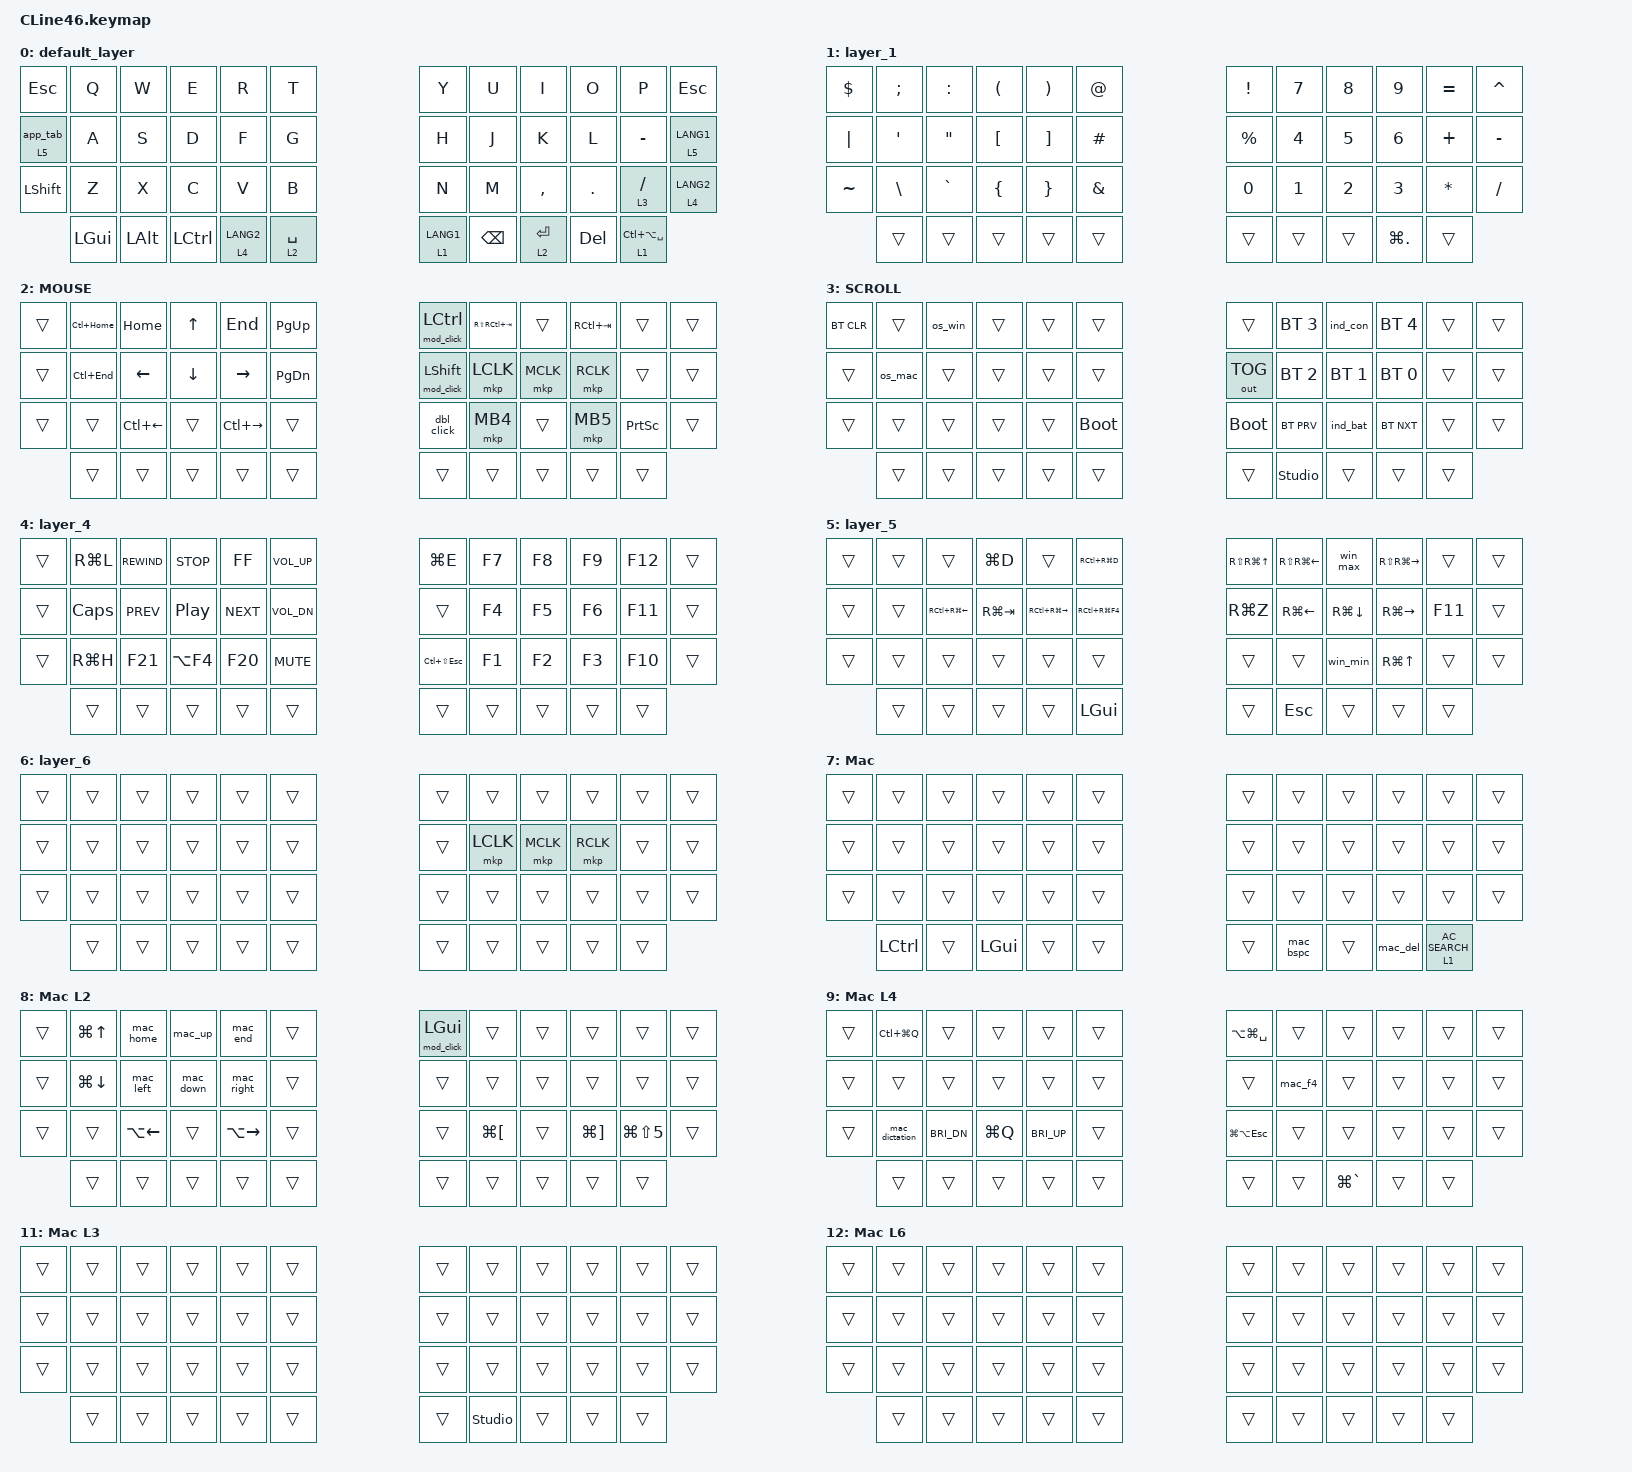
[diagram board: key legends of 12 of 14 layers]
#include <input/processors.dtsi>
#include <dt-bindings/zmk/input_transform.h>
#include <zephyr/dt-bindings/input/input-event-codes.h>
#include <behaviors.dtsi>
#include <dt-bindings/zmk/bt.h>
#include <dt-bindings/zmk/outputs.h>
#include <behaviors/rgbled_widget.dtsi>
#include <dt-bindings/zmk/keys.h>
#include <dt-bindings/zmk/pointing.h>

// ---------------------------------------------------------------------------
// レイヤー構成
//   0〜6 : 共通(Windows基準)。DYAStudio で編集してきた配列を書き写したもの
//   7    : Macモード(Windows/Macモード切替キーでON/OFF。状態は電源を切っても保持)
//   8〜12: Macモード中に、対応するレイヤーの上に自動で重なる差し替え用レイヤー
//          8 = L2(矢印・マウス)、9 = L4(メディア・F)、10 = L5(ウィンドウ操作)、11 = L3(BT)、
//          12 = L6(マウス)
// 7〜12 も DYAStudio で中身を編集できる。▽(透過)にしたキーは下のレイヤーのキーになる
// ---------------------------------------------------------------------------
#define MAC 7

// 長押しキー(A・Z など)の誤爆対策: 直前のキーから 150ms 以内に押したら長押し判定をせず、すぐ文字にする
// quick-tap: 1回タップして 200ms 以内にもう一度押したまま → 長押しではなくそのキーの押しっぱなし(連打)
&lt {
    require-prior-idle-ms = <150>;
    quick-tap-ms = <200>;
};

&mt {
    flavor = "balanced";
    quick-tap-ms = <0>;
};

/ {
    combos {
        compatible = "zmk,combos";

        tab {
            bindings = <&kp TAB>;
            key-positions = <11 12>;
        };

        shift_tab {
            bindings = <&kp LS(TAB)>;
            key-positions = <12 13>;
        };
    };

    conditional_layers {
        compatible = "zmk,conditional-layers";

        mac_nav {
            if-layers = <2 MAC>;
            then-layer = <8>;
        };

        mac_fn {
            if-layers = <4 MAC>;
            then-layer = <9>;
        };

        mac_win {
            if-layers = <5 MAC>;
            then-layer = <10>;
        };

        mac_bt {
            if-layers = <3 MAC>;
            then-layer = <11>;
        };

        mac_mouse {
            if-layers = <6 MAC>;
            then-layer = <12>;
        };

        mac_sym {
            if-layers = <1 MAC>;
            then-layer = <13>;
        };
    };

    macros {
        to_layer_0: to_layer_0 {
            compatible = "zmk,behavior-macro-one-param";
            #binding-cells = <1>;
            bindings = <&to 0 &macro_param_1to1 &kp MACRO_PLACEHOLDER>;
            label = "TO_LAYER_0";
        };

        // Mac: 音声入力(システム設定で「Controlキーを2回押す」にしておく)
        mac_dictation: mac_dictation {
            compatible = "zmk,behavior-macro";
            #binding-cells = <0>;
            display-name = "Mac Dictation";
            // 速すぎると macOS が2回押しと認識しないので、間隔を空ける
            wait-ms = <120>;
            tap-ms = <50>;
            bindings = <&macro_tap &kp LCTRL &kp LCTRL>;
        };

        // 修飾キーを押したまま左クリック(Layer 2 右手)。押している間はボタンも押しっぱなしなのでドラッグもできる
        mod_click: mod_click {
            compatible = "zmk,behavior-macro-one-param";
            #binding-cells = <1>;
            display-name = "Mod Click";
            wait-ms = <20>;
            tap-ms = <20>;
            bindings
                = <&macro_param_1to1 &macro_press &kp MACRO_PLACEHOLDER>
                , <&macro_press &mkp LCLK>
                , <&macro_pause_for_release>
                , <&macro_release &mkp LCLK>
                , <&macro_param_1to1 &macro_release &kp MACRO_PLACEHOLDER>
                ;
        };

        // Windows: 一発で画面全体に最大化(ウィンドウメニュー Alt+Space → 最大化(X))。
        // Win+↑ と違い、スナップ中でも最大化ボタンと同じ動きになる。
        // そのウィンドウで初めて開くメニューは表示が遅い(新しいウィンドウを別デスクトップへ移した直後など)ので、
        // 1.5 秒待ってから X を 0.1 秒押す(0.8 秒 / 0.03 秒では取りこぼしてメニューが開いたままになった)
        win_max: win_max {
            compatible = "zmk,behavior-macro";
            #binding-cells = <0>;
            display-name = "Maximize";
            wait-ms = <30>;
            tap-ms = <100>;
            bindings = <&macro_tap &kp LA(SPACE)>, <&macro_wait_time 1500>, <&macro_tap &kp X>;
        };

        // Windows: 最小化(ウィンドウメニュー Alt+Space → 最小化(N))。Win+↓ と違い、最大化中でも一発で最小化する。待ち時間は win_max と同じ
        win_min: win_min {
            compatible = "zmk,behavior-macro";
            #binding-cells = <0>;
            display-name = "Minimize";
            wait-ms = <30>;
            tap-ms = <100>;
            bindings = <&macro_tap &kp LA(SPACE)>, <&macro_wait_time 1500>, <&macro_tap &kp N>;
        };

        // 左ダブルクリック(Layer 2 右手)
        dbl_click: dbl_click {
            compatible = "zmk,behavior-macro";
            #binding-cells = <0>;
            display-name = "Double Click";
            wait-ms = <30>;
            tap-ms = <30>;
            bindings = <&macro_tap &mkp LCLK &mkp LCLK>;
        };

    };

    behaviors {
        lt_to_layer_0: lt_to_layer_0 {
            compatible = "zmk,behavior-hold-tap";
            label = "LAYER_TAP_TO_0";
            bindings = <&mo>, <&to_layer_0>;

            #binding-cells = <2>;
            tapping-term-ms = <200>;
            require-prior-idle-ms = <150>;
        };

        // 左 Tab: タップは App Tab、長押しはレイヤー(L5)。&lt と同じ誤爆対策を入れる
        //   使い方: &lt_app_tab 5 0(2つ目の値は使わない)
        lt_app_tab: lt_app_tab {
            compatible = "zmk,behavior-hold-tap";
            display-name = "Layer Tap App Tab";
            bindings = <&mo>, <&app_tab>;

            #binding-cells = <2>;
            flavor = "tap-preferred";
            tapping-term-ms = <200>;
            require-prior-idle-ms = <150>;
            quick-tap-ms = <200>;
        };

        // Windows/Mac モード切替
        os_win: os_win {
            compatible = "cline46,behavior-os-mode";
            #binding-cells = <0>;
            display-name = "Windows Mode";
            layer = <MAC>;
        };

        os_mac: os_mac {
            compatible = "cline46,behavior-os-mode";
            #binding-cells = <0>;
            display-name = "Mac Mode";
            layer = <MAC>;
            mac-mode;
        };

        // アプリ切替用 Tab。Mac の Cmd+Tab と同じ指(Ctrl の位置+Tab)で切り替える
        //   Windows: Ctrl+Tab → Alt+Tab / Mac: Alt+Tab → Cmd+Tab(修飾キーを離すまで切替画面を開いたまま)
        app_tab: app_tab {
            compatible = "cline46,behavior-app-tab";
            #binding-cells = <0>;
            display-name = "App Tab";
        };

        // Mac モードでは Ctrl の位置のキーが Cmd を送る。
        // Windows の Ctrl+矢印 / Ctrl+Backspace などを Mac の同じ動作に変換する
        mac_left: mac_left {
            compatible = "zmk,behavior-mod-morph";
            #binding-cells = <0>;
            display-name = "Mac Left";
            bindings = <&kp LEFT>, <&kp LA(LEFT)>;
            mods = <(MOD_LGUI|MOD_RGUI)>;
        };

        mac_right: mac_right {
            compatible = "zmk,behavior-mod-morph";
            #binding-cells = <0>;
            display-name = "Mac Right";
            bindings = <&kp RIGHT>, <&kp LA(RIGHT)>;
            mods = <(MOD_LGUI|MOD_RGUI)>;
        };

        mac_up: mac_up {
            compatible = "zmk,behavior-mod-morph";
            #binding-cells = <0>;
            display-name = "Mac Up";
            bindings = <&kp UP>, <&kp LA(UP)>;
            mods = <(MOD_LGUI|MOD_RGUI)>;
        };

        mac_down: mac_down {
            compatible = "zmk,behavior-mod-morph";
            #binding-cells = <0>;
            display-name = "Mac Down";
            bindings = <&kp DOWN>, <&kp LA(DOWN)>;
            mods = <(MOD_LGUI|MOD_RGUI)>;
        };

        // Home = 行頭(Cmd+←)、Ctrl+Home = 文書の先頭(Cmd+↑)
        mac_home: mac_home {
            compatible = "zmk,behavior-mod-morph";
            #binding-cells = <0>;
            display-name = "Mac Home";
            bindings = <&kp LG(LEFT)>, <&kp LG(UP)>;
            mods = <(MOD_LGUI|MOD_RGUI)>;
        };

        // End = 行末(Cmd+→)、Ctrl+End = 文書の末尾(Cmd+↓)
        mac_end: mac_end {
            compatible = "zmk,behavior-mod-morph";
            #binding-cells = <0>;
            display-name = "Mac End";
            bindings = <&kp LG(RIGHT)>, <&kp LG(DOWN)>;
            mods = <(MOD_LGUI|MOD_RGUI)>;
        };

        mac_bspc: mac_bspc {
            compatible = "zmk,behavior-mod-morph";
            #binding-cells = <0>;
            display-name = "Mac Backspace";
            bindings = <&kp BSPC>, <&kp LA(BSPC)>;
            mods = <(MOD_LGUI|MOD_RGUI)>;
        };

        mac_del: mac_del {
            compatible = "zmk,behavior-mod-morph";
            #binding-cells = <0>;
            display-name = "Mac Delete";
            bindings = <&kp DEL>, <&kp LA(DEL)>;
            mods = <(MOD_LGUI|MOD_RGUI)>;
        };

        // Alt+F4 → Cmd+Q
        mac_f4: mac_f4 {
            compatible = "zmk,behavior-mod-morph";
            #binding-cells = <0>;
            display-name = "Mac F4";
            bindings = <&kp F4>, <&kp LG(Q)>;
            mods = <(MOD_LALT|MOD_RALT)>;
        };
    };

    keymap {
        compatible = "zmk,keymap";

        // 長押しは左右でほぼ同じ位置に置く
        //   Space / Enter = L2、左Tab / 右Tab位置 = L5、"/" = L3、英数 / 右Shift位置 = L4、かな / 🔍 = L1
        //   左Tab のタップは App Tab。A と Z は誤爆するので長押しなし(Z は Google 日本語入力の z+h / l とぶつかる)
        //   右Tab位置のタップはかな、右Shift位置のタップは英数(左親指の英数・かなと同じキー)
        //   🔍 のタップは Windows では PowerToys Run(Ctrl+Alt+Space)、Mac では Spotlight
        default_layer {
            bindings = <
&kp ESC          &kp Q   &kp W  &kp E      &kp R        &kp T                                           &kp Y      &kp U       &kp I      &kp O    &kp P          &kp ESC
&lt_app_tab 5 0  &kp A   &kp S  &kp D      &kp F        &kp G                                           &kp H      &kp J       &kp K      &kp L    &kp MINUS      &lt 5 LANG1
&kp LSHIFT       &kp Z   &kp X  &kp C      &kp V        &kp B                                           &kp N      &kp M       &kp COMMA  &kp DOT  &lt 3 SLASH    &lt 4 LANG2
             &kp LGUI      &kp LALT   &kp LCTRL    &lt 4 LANG2  &lt 2 SPACE  &lt 1 LANG1    &kp BSPC   &lt 2 RET                         &kp DEL  &lt 1 LC(LA(SPACE))
            >;
        };

        layer_1 {
            bindings = <
&kp DLLR   &kp SEMI  &kp COLON  &kp LPAR  &kp RPAR  &kp AT                         &kp EXCL   &kp N7  &kp N8  &kp N9  &kp EQUAL  &kp CARET
&kp PIPE   &kp SQT   &kp DQT    &kp LBKT  &kp RBKT  &kp HASH                       &kp PRCNT  &kp N4  &kp N5  &kp N6  &kp PLUS   &kp MINUS
&kp TILDE  &kp BSLH  &kp GRAVE  &kp LBRC  &kp RBRC  &kp AMPS                       &kp N0     &kp N1  &kp N2  &kp N3  &kp STAR   &kp SLASH
        &trans    &trans     &trans    &trans    &trans    &trans     &trans    &trans                     &kp LG(DOT)  &trans
            >;
        };

        // 2: 矢印・マウス。左手: Q/A=文書の先頭/末尾、W/R=Home/End、T/G=PgUp/PgDn、X/V=単語左/右
        //    右手の / = スクショ(PrtSc)
        MOUSE {
            bindings = <
&trans  &kp LC(HOME)  &kp HOME   &kp UP    &kp END    &kp PG_UP                &mod_click LCTRL &kp RS(RC(TAB))  &trans    &kp RC(TAB)  &trans      &trans
&trans  &kp LC(END)   &kp LEFT   &kp DOWN  &kp RIGHT  &kp PG_DN                &mod_click LSHIFT &mkp LCLK        &mkp MCLK &mkp RCLK    &trans      &trans
&trans  &trans        &kp LC(LEFT) &trans  &kp LC(RIGHT) &trans                &dbl_click       &mkp MB4         &trans    &mkp MB5     &kp PSCRN   &trans
        &trans  &trans     &trans    &trans     &trans   &trans      &trans     &trans                                 &trans       &trans
            >;
        };

        SCROLL {
            bindings = <
&bt BT_CLR      &trans  &os_win  &trans  &trans  &trans                        &trans  &bt BT_SEL 3  &ind_con      &bt BT_SEL 4  &trans  &trans
&trans          &os_mac &trans   &trans  &trans  &trans                        &out OUT_TOG  &bt BT_SEL 2  &bt BT_SEL 1  &bt BT_SEL 0  &trans  &trans
&trans          &trans  &trans   &trans  &trans  &bootloader                   &bootloader  &bt BT_PRV    &ind_bat      &bt BT_NXT    &trans  &trans
                &trans  &trans   &trans  &trans  &trans  &trans      &studio_unlock  &trans                        &trans        &trans
            >;
        };

        // 4: メディア・ファンクション。右手内側の列は Y=エクスプローラー N=タスクマネージャー
        layer_4 {
            bindings = <
&trans  &kp RG(L)  &kp C_REWIND  &kp C_STOP  &kp C_FF    &kp C_VOL_UP                     &kp LG(E)        &kp F7  &kp F8  &kp F9  &kp F12  &trans
&trans  &kp CAPS   &kp C_PREV    &kp C_PP    &kp C_NEXT  &kp C_VOL_DN                     &trans           &kp F4  &kp F5  &kp F6  &kp F11  &trans
&trans  &kp RG(H)  &kp F21       &kp LA(F4)  &kp F20     &kp C_MUTE                       &kp LC(LS(ESC))  &kp F1  &kp F2  &kp F3  &kp F10  &trans
        &trans     &trans        &trans      &trans      &trans    &trans      &trans     &trans                  &trans  &trans
            >;
        };

        // 5: ウィンドウ操作(左Tab / 右Tab位置の長押し)
        //    小指で長押ししたまま押すので、よく使うキーは人差し指・中指の列に置く
        //    右手 = ウィンドウの移動・サイズ。矢印の形で I=最大化 J/L=左右スナップ K=元に戻す(Win+↓) ,=最小化、
        //      U/O=別モニタへ、Y=縦に最大化、H=スナップレイアウト、-=全画面(F11)、
        //      .=Win+↑(スナップ中は 1/4 に縮める)
        //    左手 = 仮想デスクトップ。右手の J/K/L と同じく S/F=前/次、D=タスクビュー、E=デスクトップ表示、T/G=作成/削除
        //    親指 = Space の位置がスタート、Backspace の位置が Esc(スナップ後の候補を閉じる)。Enter はそのまま Enter(候補を選ぶ)
        layer_5 {
            bindings = <
&trans  &trans  &trans            &kp LG(D)     &trans             &kp RC(RG(D))                &kp RS(RG(UP))  &kp RS(RG(LEFT))  &win_max      &kp RS(RG(RIGHT))  &trans      &trans
&trans  &trans  &kp RC(RG(LEFT))  &kp RG(TAB)   &kp RC(RG(RIGHT))  &kp RC(RG(F4))               &kp RG(Z)       &kp RG(LEFT)      &kp RG(DOWN)  &kp RG(RIGHT)      &kp F11     &trans
&trans  &trans  &trans            &trans        &trans             &trans                       &trans          &trans            &win_min      &kp RG(UP)         &trans      &trans
        &trans  &trans  &trans  &trans  &kp LGUI  &trans      &kp ESC  &trans                                             &trans  &trans
            >;
        };

        // 6: オートマウス(トラックボールを動かすと入る)
        layer_6 {
            bindings = <
&trans  &trans  &trans  &trans  &trans  &trans                        &trans  &trans     &trans     &trans     &trans  &trans
&trans  &trans  &trans  &trans  &trans  &trans                        &trans  &mkp LCLK  &mkp MCLK  &mkp RCLK  &trans  &trans
&trans  &trans  &trans  &trans  &trans  &trans                        &trans  &trans     &trans     &trans     &trans  &trans
        &trans  &trans  &trans  &trans  &trans  &trans      &trans    &trans                          &trans     &trans
            >;
        };

        // 7: Macモード本体。Win/Ctrl の位置を入れ替え(Ctrl の位置 = Cmd)、単語削除を変換
        //    (Alt+Tab → Cmd+Tab は Layer 0 の App Tab が Mac モードを見て切り替える)
        mac_layer {
            display-name = "Mac";
            bindings = <
&trans     &trans  &trans  &trans  &trans  &trans                            &trans  &trans  &trans  &trans  &trans  &trans
&trans     &trans  &trans  &trans  &trans  &trans                            &trans  &trans  &trans  &trans  &trans  &trans
&trans     &trans  &trans  &trans  &trans  &trans                            &trans  &trans  &trans  &trans  &trans  &trans
           &kp LCTRL       &trans  &kp LGUI  &trans  &trans  &trans    &mac_bspc  &trans                  &mac_del  &lt 1 C_AC_SEARCH
            >;
        };

        // 8: Mac版 L2(矢印・Home/End・文書の先頭/末尾・マウス用修飾・戻る/進む・スクショ)
        // Safari はマウスの戻る/進むボタンに反応しないので ⌘[ / ⌘] を送る
        mac_nav_layer {
            display-name = "Mac L2";
            bindings = <
&trans  &kp LG(UP)    &mac_home  &mac_up    &mac_end   &trans                  &mod_click LGUI &trans  &trans  &trans  &trans            &trans
&trans  &kp LG(DOWN)  &mac_left  &mac_down  &mac_right &trans                  &trans      &trans  &trans  &trans  &trans            &trans
&trans  &trans        &kp LA(LEFT) &trans   &kp LA(RIGHT) &trans               &trans      &kp LG(LBKT)  &trans  &kp LG(RBKT)  &kp LG(LS(N5))  &trans
        &trans  &trans     &trans     &trans     &trans  &trans      &trans   &trans                          &trans  &trans
            >;
        };

        // 9: Mac版 L4(ロック・音声入力・明るさ・Alt+F4・Finder・強制終了。Enter の位置=同じアプリの次のウィンドウ ⌘`)
        //    Y = Finder の検索ウィンドウ(⌥⌘Space)
        mac_fn_layer {
            display-name = "Mac L4";
            bindings = <
&trans  &kp LC(LG(Q))   &trans       &trans  &trans       &trans                    &kp LA(LG(SPACE))  &trans   &trans  &trans  &trans  &trans
&trans  &trans          &trans       &trans  &trans       &trans                    &trans             &mac_f4  &trans  &trans  &trans  &trans
&trans  &mac_dictation  &kp C_BRI_DN &kp LG(Q)  &kp C_BRI_UP &trans                 &kp LG(LA(ESC))    &trans   &trans  &trans  &trans  &trans
        &trans          &trans       &trans  &trans       &trans  &trans    &trans  &kp LG(GRAVE)               &trans  &trans
            >;
        };

        // 10: Mac版 L5(ウィンドウ操作は Rectangle の「推奨」ショートカット前提)
        //     .=上半分、最小化=⌘M、スナップレイアウトの位置=アプリExposé、タスクビューの位置=Mission Control、
        //     デスクトップ表示=F11、スタートの位置=アプリ一覧(⌃⌥⌘A。システム設定で割り当てる)
        //     仮想デスクトップの作成/削除は Mac に対応するショートカットが無いので無効
        //     Backspace の位置の Esc は、Mac モード本体(7)の Mac Backspace に隠されるのでここにも置く
        mac_win_layer {
            display-name = "Mac L5";
            bindings = <
&trans  &trans  &trans        &kp F11     &trans         &none                     &kp LC(LA(LS(UP)))  &kp LC(LA(LG(LEFT)))  &kp LC(LA(RET))   &kp LC(LA(LG(RIGHT)))  &trans          &trans
&trans  &trans  &kp LC(LEFT)  &kp LC(UP)  &kp LC(RIGHT)  &none                     &kp LC(DOWN)        &kp LC(LA(LEFT))      &kp LC(LA(BSPC))  &kp LC(LA(RIGHT))      &kp LC(LG(F))   &trans
&trans  &trans  &trans        &trans      &trans         &trans                    &trans              &trans                &kp LG(M)         &kp LC(LA(UP))         &trans          &trans
        &trans  &trans  &trans  &trans  &kp LC(LA(LG(A)))  &trans      &kp ESC  &trans                                           &trans  &trans
            >;
        };

        // 11: Mac版 L3。Macモード本体(7)が上書きするキー位置を L3 のキーに戻す
        mac_bt_layer {
            display-name = "Mac L3";
            bindings = <
&trans          &trans  &trans  &trans  &trans  &trans                        &trans  &trans  &trans  &trans  &trans  &trans
&trans          &trans  &trans  &trans  &trans  &trans                        &trans  &trans  &trans  &trans  &trans  &trans
&trans          &trans  &trans  &trans  &trans  &trans                        &trans  &trans  &trans  &trans  &trans  &trans
                &trans  &trans  &trans  &trans  &trans  &trans      &studio_unlock  &trans                &trans  &trans
            >;
        };

        // 12: Mac版 L6(今は差し替えるキーが無いので空。レイヤー番号をずらさないために残している)
        mac_mouse_layer {
            display-name = "Mac L6";
            bindings = <
&trans  &trans  &trans  &trans  &trans  &trans                        &trans  &trans        &trans  &trans        &trans  &trans
&trans  &trans  &trans  &trans  &trans  &trans                        &trans  &trans        &trans  &trans        &trans  &trans
&trans  &trans  &trans  &trans  &trans  &trans                        &trans  &trans        &trans  &trans        &trans  &trans
        &trans  &trans  &trans  &trans  &trans  &trans      &trans    &trans                                      &trans  &trans
            >;
        };

        // 13: Mac版 L1(🔍 の位置の絵文字を ⌃⌘Space に)
        mac_sym_layer {
            display-name = "Mac L1";
            bindings = <
&trans  &trans  &trans  &trans  &trans  &trans                        &trans  &trans  &trans  &trans  &trans  &trans
&trans  &trans  &trans  &trans  &trans  &trans                        &trans  &trans  &trans  &trans  &trans  &trans
&trans  &trans  &trans  &trans  &trans  &trans                        &trans  &trans  &trans  &trans  &trans  &trans
        &trans  &trans  &trans  &trans  &trans  &trans      &trans    &trans                          &kp LC(LG(SPACE))  &trans
            >;
        };
    };
};
